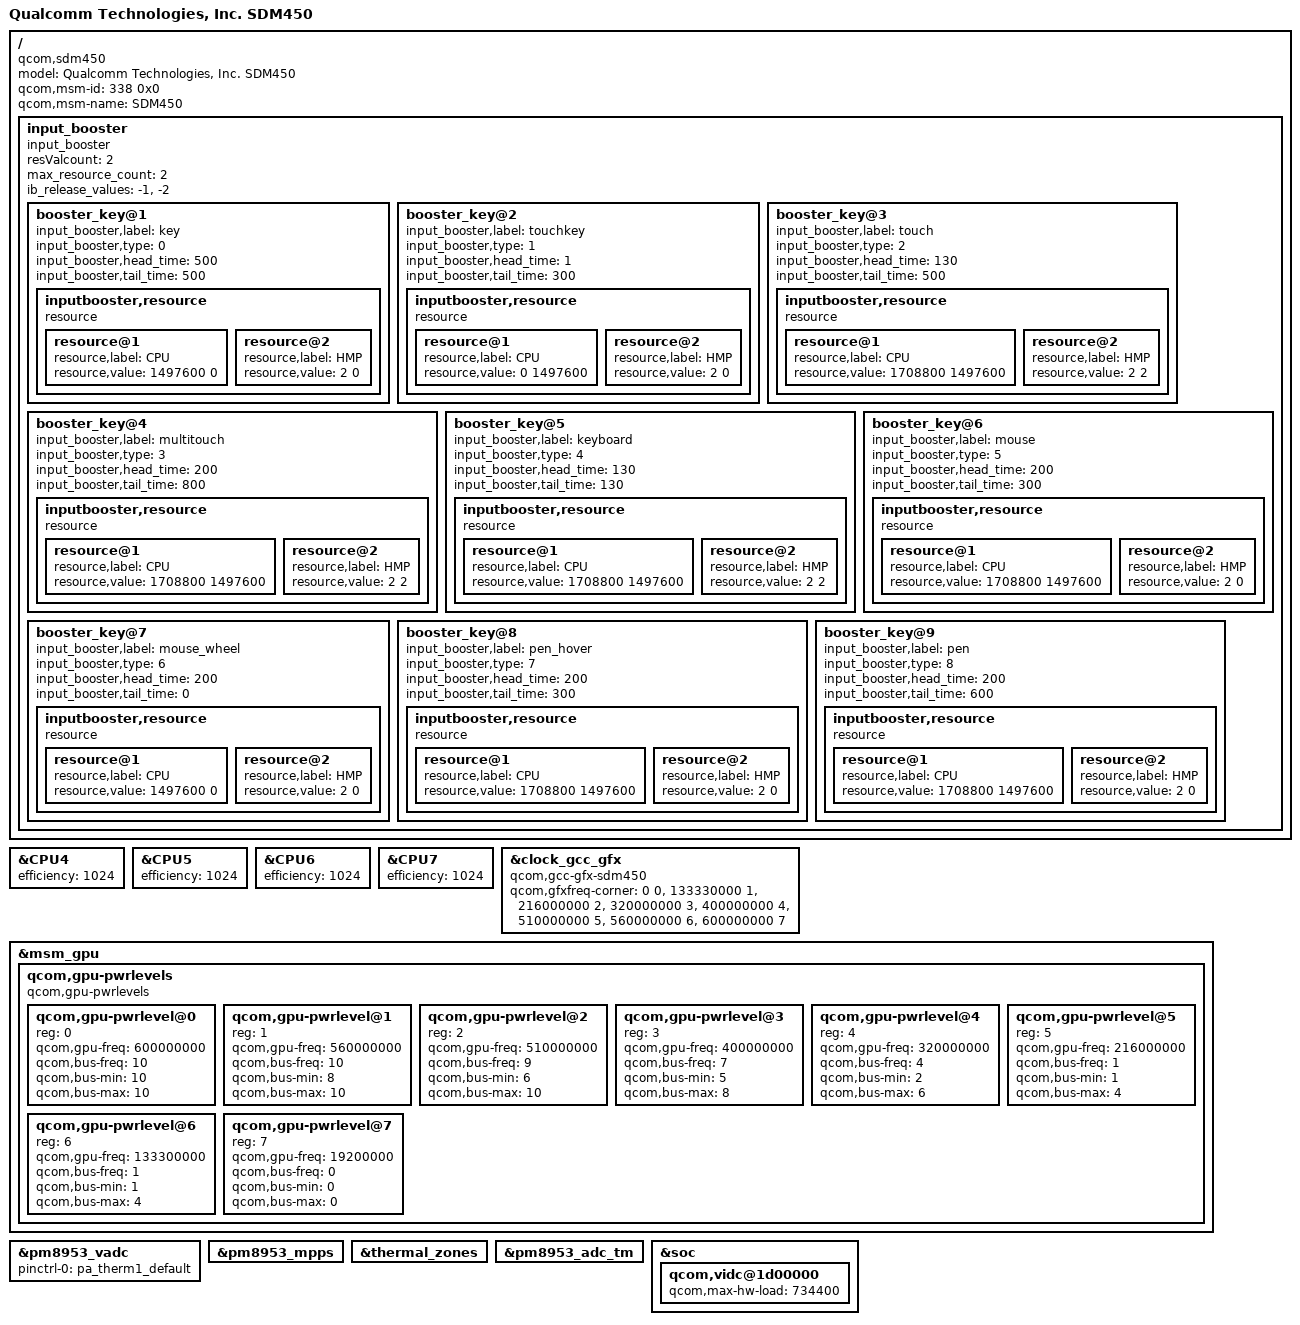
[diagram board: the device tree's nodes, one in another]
/*
 * Copyright (c) 2017-2018, 2021 The Linux Foundation. All rights reserved.
 *
 * This program is free software; you can redistribute it and/or modify
 * it under the terms of the GNU General Public License version 2 and
 * only version 2 as published by the Free Software Foundation.
 *
 * This program is distributed in the hope that it will be useful,
 * but WITHOUT ANY WARRANTY; without even the implied warranty of
 * MERCHANTABILITY or FITNESS FOR A PARTICULAR PURPOSE.  See the
 * GNU General Public License for more details.
 */

#include "msm8953.dtsi"

/ {
	model = "Qualcomm Technologies, Inc. SDM450";
	compatible = "qcom,sdm450";
	qcom,msm-id = <338 0x0>;
	qcom,msm-name = "SDM450";

	input_booster {
		status = "okay";
		compatible = "input_booster";
		resValcount = "2";
		max_resource_count = "2";
		#address-cells = <1>;
		#size-cells = <0>;

		/* < CPU HMP> */
		ib_release_values = "-1, -2";

		booster_key@1 {
			input_booster,label = "key";
			input_booster,type = <0>;	/* BOOSTER_DEVICE_KEY */

			/* Time table */
			input_booster,head_time = <500>;
			input_booster,tail_time = <500>;

			/* Resource Table Sequentially identified with index
			 * CPU's ID & Index : 0
			 * HMPBOOST's ID & Index : 1
			*/

			/* Input Booster Resource Frequency */
			inputbooster,resource {
				compatible = "resource";
				resource@1 {
					resource,label = "CPU";
					resource,value = <1497600 0>;
				};

				resource@2 {
					resource,label = "HMP";
					resource,value = <2 0>;
				};
			};
		};

		booster_key@2 {
			input_booster,label = "touchkey";
			input_booster,type = <1>;	/* BOOSTER_DEVICE_TOUCHKEY */

			/* Time table */
			input_booster,head_time = <1>;
			input_booster,tail_time = <300>;

			/* Input Booster Resource Frequency */
			inputbooster,resource {
				compatible = "resource";
				resource@1 {
					resource,label = "CPU";
					resource,value = <0 1497600>;
				};

				resource@2 {
					resource,label = "HMP";
					resource,value = <2 0>;
				};
			};
		};

		booster_key@3 {
			input_booster,label = "touch";
			input_booster,type = <2>;	/* BOOSTER_DEVICE_TOUCH */

			/* Time table */
			input_booster,head_time = <130>;
			input_booster,tail_time = <500>;

			/* Input Booster Resource Frequency */
			inputbooster,resource {
				compatible = "resource";
				resource@1 {
					resource,label = "CPU";
					resource,value = <1708800 1497600>;
				};

				resource@2 {
					resource,label = "HMP";
					resource,value = <2 2>;
				};
			};
		};

		booster_key@4 {
			input_booster,label = "multitouch";
			input_booster,type = <3>;	/* BOOSTER_DEVICE_MULTITOUCH */

			/* Time table */
			input_booster,head_time = <200>;
			input_booster,tail_time = <800>;

			/* Input Booster Resource Frequency */
			inputbooster,resource {
				compatible = "resource";
				resource@1 {
					resource,label = "CPU";
					resource,value = <1708800 1497600>;
				};

				resource@2 {
					resource,label = "HMP";
					resource,value = <2 2>;
				};
			};
		};

		booster_key@5 {
			input_booster,label = "keyboard";
			input_booster,type = <4>;	/* BOOSTER_DEVICE_KEYBOARD */

			/* Time table */
			input_booster,head_time = <130>;
			input_booster,tail_time = <130>;

			/* Input Booster Resource Frequency */
			inputbooster,resource {
				compatible = "resource";
				resource@1 {
					resource,label = "CPU";
					resource,value = <1708800 1497600>;
				};

				resource@2 {
					resource,label = "HMP";
					resource,value = <2 2>;
				};
			};
		};

		booster_key@6 {
			input_booster,label = "mouse";
			input_booster,type = <5>;	/* BOOSTER_DEVICE_MOUSE */

			/* Time table */
			input_booster,head_time = <200>;
			input_booster,tail_time = <300>;

			/* Input Booster Resource Frequency */
			inputbooster,resource {
				compatible = "resource";
				resource@1 {
					resource,label = "CPU";
					resource,value = <1708800 1497600>;
				};

				resource@2 {
					resource,label = "HMP";
					resource,value = <2 0>;
				};

			};
		};

		booster_key@7 {
			input_booster,label = "mouse_wheel";
			input_booster,type = <6>;	/* BOOSTER_DEVICE_MOUSE */

			/* Time table */
			input_booster,head_time = <200>;
			input_booster,tail_time = <0>;

			/* Input Booster Resource Frequency */
			inputbooster,resource {
				compatible = "resource";
				resource@1 {
					resource,label = "CPU";
					resource,value = <1497600 0>;
				};

				resource@2 {
					resource,label = "HMP";
					resource,value = <2 0>;
				};

			};
		};

		booster_key@8 {
			input_booster,label = "pen_hover";
			input_booster,type = <7>;	/* BOOSTER_DEVICE_MOUSE */

			/* Time table */
			input_booster,head_time = <200>;
			input_booster,tail_time = <300>;

			/* Input Booster Resource Frequency */
			inputbooster,resource {
				compatible = "resource";
				resource@1 {
					resource,label = "CPU";
					resource,value = <1708800 1497600>;
				};

				resource@2 {
					resource,label = "HMP";
					resource,value = <2 0>;
				};

			};
		};

		booster_key@9 {
			input_booster,label = "pen";
			input_booster,type = <8>;	/* BOOSTER_DEVICE_MOUSE */

			/* Time table */
			input_booster,head_time = <200>;
			input_booster,tail_time = <600>;

			/* Input Booster Resource Frequency */
			inputbooster,resource {
				compatible = "resource";
				resource@1 {
					resource,label = "CPU";
					resource,value = <1708800 1497600>;
				};

				resource@2 {
					resource,label = "HMP";
					resource,value = <2 0>;
				};

			};
		};
		/* If you need to add new key type, add it this position */
	};
};

&CPU4 {
	efficiency = <1024>;
};

&CPU5 {
	efficiency = <1024>;
};

&CPU6 {
	efficiency = <1024>;
};

&CPU7 {
	efficiency = <1024>;
};

&clock_gcc_gfx {
	compatible = "qcom,gcc-gfx-sdm450";
	qcom,gfxfreq-corner =
		<         0   0 >,
		< 133330000   1 >,  /* Min SVS   */
		< 216000000   2 >,  /* Low SVS   */
		< 320000000   3 >,  /* SVS       */
		< 400000000   4 >,  /* SVS Plus  */
		< 510000000   5 >,  /* NOM       */
		< 560000000   6 >,  /* Nom Plus  */
		< 600000000   7 >;  /* Turbo     */
};

/* GPU Overrides*/
&msm_gpu {

	/delete-node/qcom,gpu-pwrlevels;

	qcom,gpu-pwrlevels {
		#address-cells = <1>;
		#size-cells = <0>;

		compatible = "qcom,gpu-pwrlevels";

		/* TURBO */
		qcom,gpu-pwrlevel@0 {
			reg = <0>;
			qcom,gpu-freq = <600000000>;
			qcom,bus-freq = <10>;
			qcom,bus-min = <10>;
			qcom,bus-max = <10>;
		};

		/* NOM+ */
		qcom,gpu-pwrlevel@1 {
			reg = <1>;
			qcom,gpu-freq = <560000000>;
			qcom,bus-freq = <10>;
			qcom,bus-min = <8>;
			qcom,bus-max = <10>;
		};

		/* NOM */
		qcom,gpu-pwrlevel@2 {
			reg = <2>;
			qcom,gpu-freq = <510000000>;
			qcom,bus-freq = <9>;
			qcom,bus-min = <6>;
			qcom,bus-max = <10>;
		};

		/* SVS+ */
		qcom,gpu-pwrlevel@3 {
			reg = <3>;
			qcom,gpu-freq = <400000000>;
			qcom,bus-freq = <7>;
			qcom,bus-min = <5>;
			qcom,bus-max = <8>;
		};

		/* SVS */
		qcom,gpu-pwrlevel@4 {
			reg = <4>;
			qcom,gpu-freq = <320000000>;
			qcom,bus-freq = <4>;
			qcom,bus-min = <2>;
			qcom,bus-max = <6>;
		};

		/* Low SVS */
		qcom,gpu-pwrlevel@5 {
			reg = <5>;
			qcom,gpu-freq = <216000000>;
			qcom,bus-freq = <1>;
			qcom,bus-min = <1>;
			qcom,bus-max = <4>;
		};

		/* Min SVS */
		qcom,gpu-pwrlevel@6 {
			reg = <6>;
			qcom,gpu-freq = <133300000>;
			qcom,bus-freq = <1>;
			qcom,bus-min = <1>;
			qcom,bus-max = <4>;
		};
		/* XO */
		qcom,gpu-pwrlevel@7 {
			reg = <7>;
			qcom,gpu-freq = <19200000>;
			qcom,bus-freq = <0>;
			qcom,bus-min = <0>;
			qcom,bus-max = <0>;
		};
	};
};

&pm8953_vadc {
	pinctrl-0 = <&pa_therm1_default>;
	/delete-node/ chan@13;
};

&pm8953_mpps {
	/delete-node/ case_therm;
};

&thermal_zones {
	/delete-node/ case-therm-adc;
	/delete-node/ case-therm-step;
};
/* HS70 add for HS70-196 replace xo-therm with MSM-therm in adc_tm by qianyingdong at 2019/10/31 start */
&pm8953_adc_tm {
	/delete-node/ chan@32;
};
/* HS70 add for HS70-196 replace xo-therm with MSM-therm in adc_tm by qianyingdong at 2019/10/31 end */
&soc {
	qcom,vidc@1d00000 {
		qcom,max-hw-load = <734400>; /* 1080p@60 dec + 1080p@30 enc */
	};
};
